# EFR32FG23B021F512IM48 register map
Vendor: Silicon Labs; Series: EFR32; File version: C
CPU: CM33 r0p4, little endian, MPU, FPU, DSP, VTOR, 4 interrupt priority bits, 8 SAU regions
Registers are 32-bit, read-write, reset 0x0 unless marked. A register's access mark holds for its fields unless they carry their own. Offsets are from the block's base; [hi:lo] are bit positions; {n}, {i} and the like mark numbered series.

## USART0_NS — USART0_NS Registers
Base 0x5005C000
Same registers: USART0_S 0x4005C000
0x00 IPVERSION ro
0x04 EN
  [0] EN — USART Enable
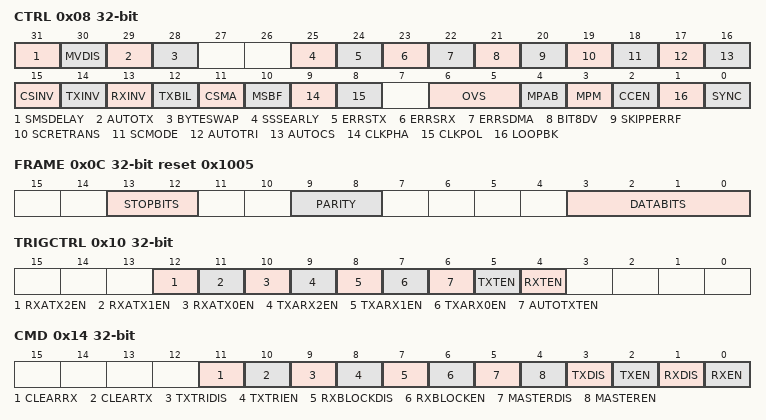
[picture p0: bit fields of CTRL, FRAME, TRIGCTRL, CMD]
0x08 CTRL
  [31] SMSDELAY — Synchronous Main Sample Delay
  [30] MVDIS — Majority Vote Disable
  [29] AUTOTX — Always Transmit When RX Not Full
  [28] BYTESWAP — Byteswap In Double Accesses
    0=DISABLE (Normal byte order); 1=ENABLE (Byte order swapped)
  [25] SSSEARLY — Synchronous Secondary Setup Early
  [24] ERRSTX — Disable TX On Error
    0=DISABLE (Received framing and parity errors have no effect on transmitter); 1=ENABLE (Received framing and parity errors disable the transmitter)
  [23] ERRSRX — Disable RX On Error
    0=DISABLE (Framing and parity errors have no effect on receiver); 1=ENABLE (Framing and parity errors disable the receiver)
  [22] ERRSDMA — Halt DMA On Error
    0=DISABLE (Framing and parity errors have no effect on DMA requests from the USART); 1=ENABLE (DMA requests from the USART are blocked while the PERR or FERR interrupt flags are set)
  [21] BIT8DV — Bit 8 Default Value
  [20] SKIPPERRF — Skip Parity Error Frames
  [19] SCRETRANS — SmartCard Retransmit
  [18] SCMODE — SmartCard Mode
  [17] AUTOTRI — Automatic TX Tristate
    0=DISABLE (The output on U(S)n_TX when the transmitter is idle is defined by TXINV); 1=ENABLE (U(S)n_TX is tristated whenever the transmitter is idle)
  [16] AUTOCS — Automatic Chip Select
  [15] CSINV — Chip Select Invert
    0=DISABLE (Chip select is active low); 1=ENABLE (Chip select is active high)
  [14] TXINV — Transmitter output Invert
    0=DISABLE (Output from the transmitter is passed unchanged to U(S)n_TX); 1=ENABLE (Output from the transmitter is inverted before it is passed to U(S)n_TX)
  [13] RXINV — Receiver Input Invert
    0=DISABLE (Input is passed directly to the receiver); 1=ENABLE (Input is inverted before it is passed to the receiver)
  [12] TXBIL — TX Buffer Interrupt Level
    0=EMPTY (TXBL and the TXBL interrupt flag are set when the transmit buffer becomes empty. TXBL is cleared when the buffer becomes nonempty.); 1=HALFFULL (TXBL and TXBLIF are set when the transmit buffer goes from full to half-full or empty. TXBL is cleared when the buffer becomes full.)
  [11] CSMA — Action On Chip Select In Main Mode
    0=NOACTION (No action taken); 1=GOTOSLAVEMODE (Go to secondary mode)
  [10] MSBF — Most Significant Bit First
    0=DISABLE (Data is sent with the least significant bit first); 1=ENABLE (Data is sent with the most significant bit first)
  [9] CLKPHA — Clock Edge For Setup/Sample
    0=SAMPLELEADING (Data is sampled on the leading edge and set-up on the trailing edge of the bus clock in synchronous mode); 1=SAMPLETRAILING (Data is set-up on the leading edge and sampled on the trailing edge of the bus clock in synchronous mode)
  [8] CLKPOL — Clock Polarity
    0=IDLELOW (The bus clock used in synchronous mode has a low base value); 1=IDLEHIGH (The bus clock used in synchronous mode has a high base value)
  [6:5] OVS — Oversampling
    0=X16 (Regular UART mode with 16X oversampling in asynchronous mode); 1=X8 (Double speed with 8X oversampling in asynchronous mode); 2=X6 (6X oversampling in asynchronous mode); 3=X4 (Quadruple speed with 4X oversampling in asynchronous mode)
  [4] MPAB — Multi-Processor Address-Bit
  [3] MPM — Multi-Processor Mode
    0=DISABLE (The 9th bit of incoming frames has no special function); 1=ENABLE (An incoming frame with the 9th bit equal to MPAB will be loaded into the receive buffer regardless of RXBLOCK and will result in the MPAB interrupt flag being set)
  [2] CCEN — Collision Check Enable
    0=DISABLE (Collision check is disabled); 1=ENABLE (Collision check is enabled. The receiver must be enabled for the check to be performed)
  [1] LOOPBK — Loopback Enable
    0=DISABLE (The receiver is connected to and receives data from U(S)n_RX); 1=ENABLE (The receiver is connected to and receives data from U(S)n_TX)
  [0] SYNC — USART Synchronous Mode
    0=DISABLE (The USART operates in asynchronous mode); 1=ENABLE (The USART operates in synchronous mode)
0x0C FRAME reset 0x1005
  [13:12] STOPBITS — Stop-Bit Mode
    0=HALF (The transmitter generates a half stop bit. Stop-bits are not verified by receiver); 1=ONE (One stop bit is generated and verified); 2=ONEANDAHALF (The transmitter generates one and a half stop bit. The receiver verifies the first stop bit); 3=TWO (The transmitter generates two stop bits. The receiver checks the first stop-bit only)
  [9:8] PARITY — Parity-Bit Mode
    0=NONE (Parity bits are not used); 2=EVEN (Even parity are used. Parity bits are automatically generated and checked by hardware.); 3=ODD (Odd parity is used. Parity bits are automatically generated and checked by hardware.)
  [3:0] DATABITS — Data-Bit Mode
    1=FOUR (Each frame contains 4 data bits); 2=FIVE (Each frame contains 5 data bits); 3=SIX (Each frame contains 6 data bits); 4=SEVEN (Each frame contains 7 data bits); 5=EIGHT (Each frame contains 8 data bits); 6=NINE (Each frame contains 9 data bits); 7=TEN (Each frame contains 10 data bits); 8=ELEVEN (Each frame contains 11 data bits); 9=TWELVE (Each frame contains 12 data bits); 10=THIRTEEN (Each frame contains 13 data bits); 11=FOURTEEN (Each frame contains 14 data bits); 12=FIFTEEN (Each frame contains 15 data bits); 13=SIXTEEN (Each frame contains 16 data bits)
0x10 TRIGCTRL
  [12] RXATX2EN — Enable Receive Trigger after TX end of f
  [11] RXATX1EN — Enable Receive Trigger after TX end of f
  [10] RXATX0EN — Enable Receive Trigger after TX end of f
  [9] TXARX2EN — Enable Transmit Trigger after RX End of
  [8] TXARX1EN — Enable Transmit Trigger after RX End of
  [7] TXARX0EN — Enable Transmit Trigger after RX End of
  [6] AUTOTXTEN — AUTOTX Trigger Enable
  [5] TXTEN — Transmit Trigger Enable
  [4] RXTEN — Receive Trigger Enable
0x14 CMD wo
  [11] CLEARRX
  [10] CLEARTX
  [9] TXTRIDIS — Transmitter Tristate Disable
  [8] TXTRIEN — Transmitter Tristate Enable
  [7] RXBLOCKDIS — Receiver Block Disable
  [6] RXBLOCKEN — Receiver Block Enable
  [5] MASTERDIS — Main Mode Disable
  [4] MASTEREN — Main Mode Enable
  [3] TXDIS — Transmitter Disable
  [2] TXEN — Transmitter Enable
  [1] RXDIS — Receiver Disable
  [0] RXEN — Receiver Enable
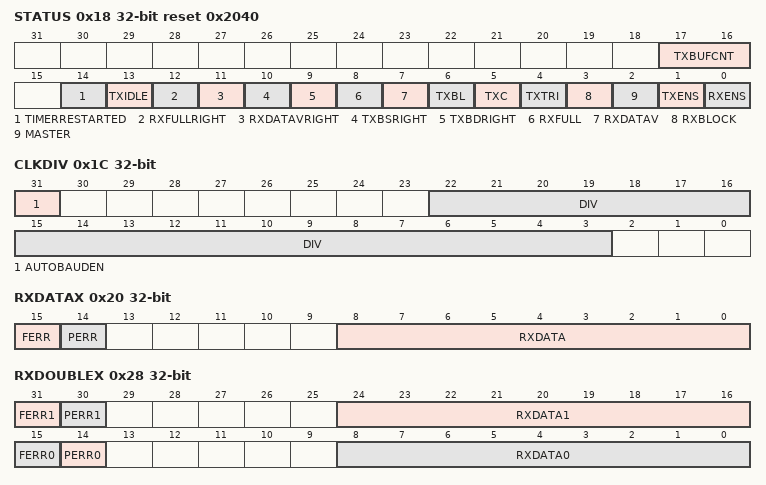
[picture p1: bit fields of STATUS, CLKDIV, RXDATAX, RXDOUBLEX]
0x18 STATUS ro reset 0x2040
  [17:16] TXBUFCNT — TX Buffer Count
  [14] TIMERRESTARTED — The USART Timer restarted itself
  [13] TXIDLE
  [12] RXFULLRIGHT — RX Full of Right Data
  [11] RXDATAVRIGHT — RX Data Right
  [10] TXBSRIGHT — TX Buffer Expects Single Right Data
  [9] TXBDRIGHT — TX Buffer Expects Double Right Data
  [8] RXFULL — RX FIFO Full
  [7] RXDATAV — RX Data Valid
  [6] TXBL — TX Buffer Level
  [5] TXC — TX Complete
  [4] TXTRI — Transmitter Tristated
  [3] RXBLOCK — Block Incoming Data
  [2] MASTER — SPI Main Mode
  [1] TXENS — Transmitter Enable Status
  [0] RXENS — Receiver Enable Status
0x1C CLKDIV
  [31] AUTOBAUDEN — AUTOBAUD detection enable
  [22:3] DIV — Fractional Clock Divider
0x20 RXDATAX ro
  [15] FERR — Data Framing Error
  [14] PERR — Data Parity Error
  [8:0] RXDATA
0x24 RXDATA ro
  [7:0] RXDATA
0x28 RXDOUBLEX ro
  [31] FERR1 — Data Framing Error 1
  [30] PERR1 — Data Parity Error 1
  [24:16] RXDATA1
  [15] FERR0 — Data Framing Error 0
  [14] PERR0 — Data Parity Error 0
  [8:0] RXDATA0
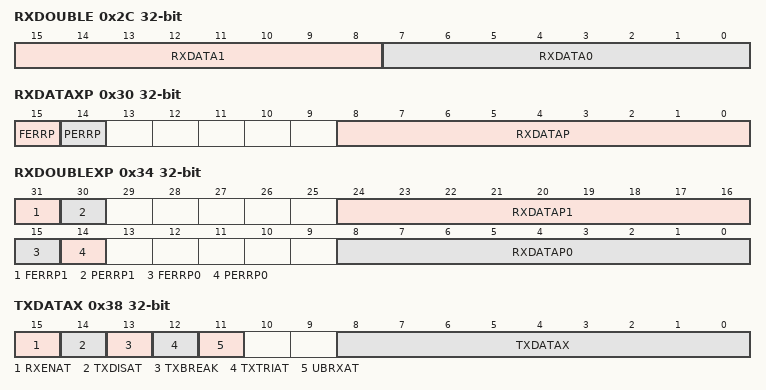
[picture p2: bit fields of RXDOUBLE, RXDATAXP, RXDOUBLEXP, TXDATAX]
0x2C RXDOUBLE ro
  [15:8] RXDATA1, [7:0] RXDATA0
0x30 RXDATAXP ro
  [15] FERRP — Data Framing Error Peek
  [14] PERRP — Data Parity Error Peek
  [8:0] RXDATAP — RX Data Peek
0x34 RXDOUBLEXP ro
  [31] FERRP1 — Data Framing Error 1 Peek
  [30] PERRP1 — Data Parity Error 1 Peek
  [24:16] RXDATAP1 — RX Data 1 Peek
  [15] FERRP0 — Data Framing Error 0 Peek
  [14] PERRP0 — Data Parity Error 0 Peek
  [8:0] RXDATAP0 — RX Data 0 Peek
0x38 TXDATAX wo
  [15] RXENAT — Enable RX After Transmission
  [14] TXDISAT — Clear TXEN After Transmission
  [13] TXBREAK — Transmit Data As Break
  [12] TXTRIAT — Set TXTRI After Transmission
  [11] UBRXAT — Unblock RX After Transmission
  [8:0] TXDATAX — TX Data
0x3C TXDATA wo
  [7:0] TXDATA
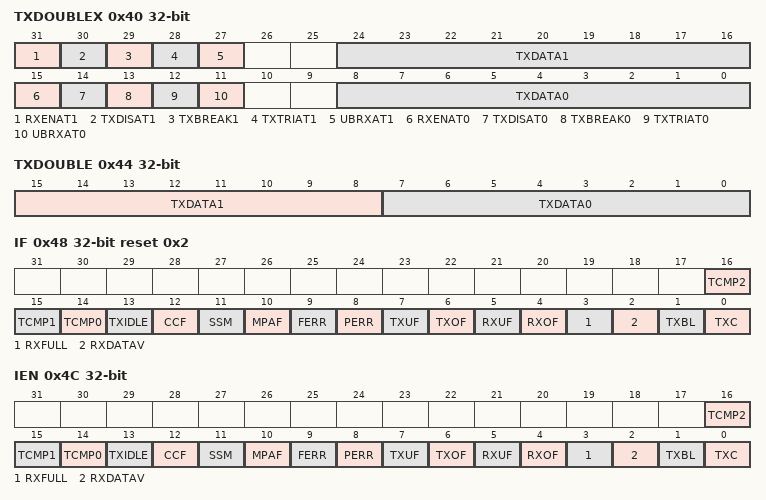
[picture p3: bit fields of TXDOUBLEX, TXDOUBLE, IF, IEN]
0x40 TXDOUBLEX wo
  [31] RXENAT1 — Enable RX After Transmission
  [30] TXDISAT1 — Clear TXEN After Transmission
  [29] TXBREAK1 — Transmit Data As Break
  [28] TXTRIAT1 — Set TXTRI After Transmission
  [27] UBRXAT1 — Unblock RX After Transmission
  [24:16] TXDATA1 — TX Data
  [15] RXENAT0 — Enable RX After Transmission
  [14] TXDISAT0 — Clear TXEN After Transmission
  [13] TXBREAK0 — Transmit Data As Break
  [12] TXTRIAT0 — Set TXTRI After Transmission
  [11] UBRXAT0 — Unblock RX After Transmission
  [8:0] TXDATA0 — TX Data
0x44 TXDOUBLE wo
  [15:8] TXDATA1 — TX Data
  [7:0] TXDATA0 — TX Data
0x48 IF reset 0x2
  [16] TCMP2 — Timer comparator 2 Interrupt Flag
  [15] TCMP1 — Timer comparator 1 Interrupt Flag
  [14] TCMP0 — Timer comparator 0 Interrupt Flag
  [13] TXIDLE — TX Idle Interrupt Flag
  [12] CCF — Collision Check Fail Interrupt Flag
  [11] SSM — Chip-Select In Main Mode Interrupt Flag
  [10] MPAF — Multi-Processor Address Frame Interrupt
  [9] FERR — Framing Error Interrupt Flag
  [8] PERR — Parity Error Interrupt Flag
  [7] TXUF — TX Underflow Interrupt Flag
  [6] TXOF — TX Overflow Interrupt Flag
  [5] RXUF — RX Underflow Interrupt Flag
  [4] RXOF — RX Overflow Interrupt Flag
  [3] RXFULL — RX Buffer Full Interrupt Flag
  [2] RXDATAV — RX Data Valid Interrupt Flag
  [1] TXBL — TX Buffer Level Interrupt Flag
  [0] TXC — TX Complete Interrupt Flag
0x4C IEN
  [16] TCMP2 — Timer comparator 2 Interrupt Enable
  [15] TCMP1 — Timer comparator 1 Interrupt Enable
  [14] TCMP0 — Timer comparator 0 Interrupt Enable
  [13] TXIDLE — TX Idle Interrupt Enable
  [12] CCF — Collision Check Fail Interrupt Enable
  [11] SSM — Chip-Select In Main Mode Interrupt Flag
  [10] MPAF — Multi-Processor Address Frame Interrupt
  [9] FERR — Framing Error Interrupt Enable
  [8] PERR — Parity Error Interrupt Enable
  [7] TXUF — TX Underflow Interrupt Enable
  [6] TXOF — TX Overflow Interrupt Enable
  [5] RXUF — RX Underflow Interrupt Enable
  [4] RXOF — RX Overflow Interrupt Enable
  [3] RXFULL — RX Buffer Full Interrupt Enable
  [2] RXDATAV — RX Data Valid Interrupt Enable
  [1] TXBL — TX Buffer Level Interrupt Enable
  [0] TXC — TX Complete Interrupt Enable
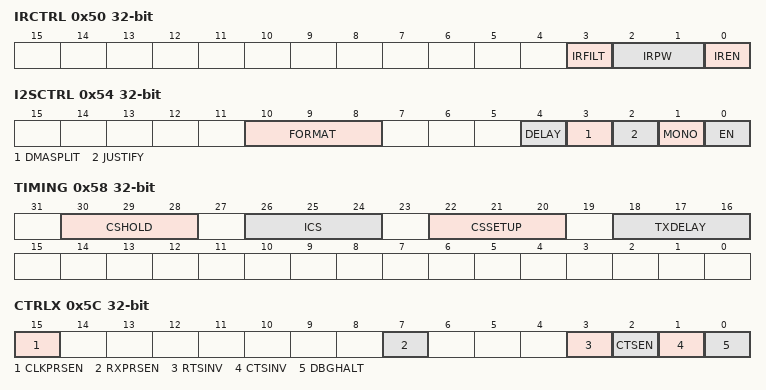
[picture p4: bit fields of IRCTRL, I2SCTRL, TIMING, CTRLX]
0x50 IRCTRL
  [3] IRFILT — IrDA RX Filter
    0=DISABLE (No filter enabled); 1=ENABLE (Filter enabled. IrDA pulse must be high for at least 5 consecutive clock cycles to be detected)
  [2:1] IRPW — IrDA TX Pulse Width
    0=ONE (IrDA pulse width is 1/16 for OVS=0 and 1/8 for OVS=1); 1=TWO (IrDA pulse width is 2/16 for OVS=0 and 2/8 for OVS=1); 2=THREE (IrDA pulse width is 3/16 for OVS=0 and 3/8 for OVS=1); 3=FOUR (IrDA pulse width is 4/16 for OVS=0 and 4/8 for OVS=1)
  [0] IREN — Enable IrDA Module
0x54 I2SCTRL
  [10:8] FORMAT — I2S Word Format
    0=W32D32 (32-bit word, 32-bit data); 1=W32D24M (32-bit word, 32-bit data with 8 lsb masked); 2=W32D24 (32-bit word, 24-bit data); 3=W32D16 (32-bit word, 16-bit data); 4=W32D8 (32-bit word, 8-bit data); 5=W16D16 (16-bit word, 16-bit data); 6=W16D8 (16-bit word, 8-bit data); 7=W8D8 (8-bit word, 8-bit data)
  [4] DELAY — Delay on I2S data
  [3] DMASPLIT — Separate DMA Request For Left/Right Data
  [2] JUSTIFY — Justification of I2S Data
    0=LEFT (Data is left-justified); 1=RIGHT (Data is right-justified)
  [1] MONO — Stero or Mono
  [0] EN — Enable I2S Mode
0x58 TIMING
  [30:28] CSHOLD — Chip Select Hold
    0=ZERO (Disable CS being asserted after the end of transmission); 1=ONE (CS is asserted for 1 baud-times after the end of transmission); 2=TWO (CS is asserted for 2 baud-times after the end of transmission); 3=THREE (CS is asserted for 3 baud-times after the end of transmission); 4=SEVEN (CS is asserted for 7 baud-times after the end of transmission); 5=TCMP0 (CS is asserted after the end of transmission for TCMPVAL0 baud-times); 6=TCMP1 (CS is asserted after the end of transmission for TCMPVAL1 baud-times); 7=TCMP2 (CS is asserted after the end of transmission for TCMPVAL2 baud-times)
  [26:24] ICS — Inter-character spacing
    0=ZERO (There is no space between charcters); 1=ONE (Create a space of 1 baud-times before start of transmission); 2=TWO (Create a space of 2 baud-times before start of transmission); 3=THREE (Create a space of 3 baud-times before start of transmission); 4=SEVEN (Create a space of 7 baud-times before start of transmission); 5=TCMP0 (Create a space of before the start of transmission for TCMPVAL0 baud-times); 6=TCMP1 (Create a space of before the start of transmission for TCMPVAL1 baud-times); 7=TCMP2 (Create a space of before the start of transmission for TCMPVAL2 baud-times)
  [22:20] CSSETUP — Chip Select Setup
    0=ZERO (CS is not asserted before start of transmission); 1=ONE (CS is asserted for 1 baud-times before start of transmission); 2=TWO (CS is asserted for 2 baud-times before start of transmission); 3=THREE (CS is asserted for 3 baud-times before start of transmission); 4=SEVEN (CS is asserted for 7 baud-times before start of transmission); 5=TCMP0 (CS is asserted before the start of transmission for TCMPVAL0 baud-times); 6=TCMP1 (CS is asserted before the start of transmission for TCMPVAL1 baud-times); 7=TCMP2 (CS is asserted before the start of transmission for TCMPVAL2 baud-times)
  [18:16] TXDELAY — TX frame start delay
    0=DISABLE (Disable - TXDELAY in USARTn_CTRL can be used for legacy); 1=ONE (Start of transmission is delayed for 1 baud-times); 2=TWO (Start of transmission is delayed for 2 baud-times); 3=THREE (Start of transmission is delayed for 3 baud-times); 4=SEVEN (Start of transmission is delayed for 7 baud-times); 5=TCMP0 (Start of transmission is delayed for TCMPVAL0 baud-times); 6=TCMP1 (Start of transmission is delayed for TCMPVAL1 baud-times); 7=TCMP2 (Start of transmission is delayed for TCMPVAL2 baud-times)
0x5C CTRLX
  [15] CLKPRSEN — PRS CLK Enable
  [7] RXPRSEN — PRS RX Enable
  [3] RTSINV — RTS Pin Inversion
    0=DISABLE (The USn_RTS pin is low true); 1=ENABLE (The USn_RTS pin is high true)
  [2] CTSEN — CTS Function enabled
    0=DISABLE (Ingore CTS); 1=ENABLE (Stop transmitting when CTS is negated)
  [1] CTSINV — CTS Pin Inversion
    0=DISABLE (The USn_CTS pin is low true); 1=ENABLE (The USn_CTS pin is high true)
  [0] DBGHALT — Debug halt
    0=DISABLE (Continue to transmit until TX buffer is empty); 1=ENABLE (Negate RTS to stop link partner's transmission during debug HALT. NOTE** The core clock should be equal to or faster than the peripheral clock; otherwise, each single step could transmit multiple frames instead of just transmitting one frame.)
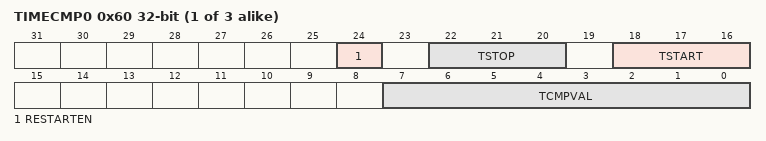
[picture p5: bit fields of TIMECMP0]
{0x60+4i} TIMECMP{i} (i=0..2)
  [24] RESTARTEN — Restart Timer on TCMP{i}
    0=DISABLE (Disable the timer restarting on TCMP{i}); 1=ENABLE (Enable the timer restarting on TCMP{i})
  [22:20] TSTOP — Source used to disable comparator {i}
    0=TCMP{i} (Comparator {i} is disabled when the counter equals TCMPVAL and triggers a TCMP{i} event); 1=TXST (Comparator {i} is disabled at TX start TX Engine); 2=RXACT (Comparator {i} is disabled on RX going going Active (default: low)); 3=RXACTN (Comparator {i} is disabled on RX going Inactive)
  [18:16] TSTART — Timer start source
    0=DISABLE (Comparator {i} is disabled); 1=TXEOF (Comparator {i} and timer are started at TX end of frame); 2=TXC (Comparator {i} and timer are started at TX Complete); 3=RXACT (Comparator {i} and timer are started at RX going going Active (default: low)); 4=RXEOF (Comparator {i} and timer are started at RX end of frame)
  [7:0] TCMPVAL — Timer comparator {i}.
